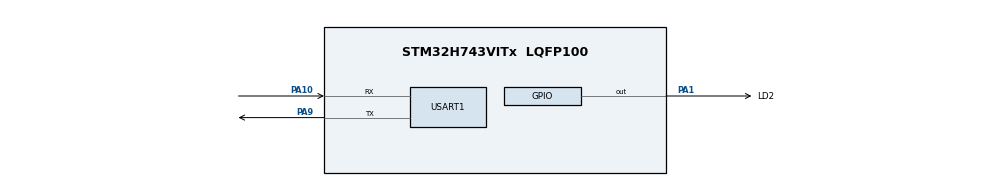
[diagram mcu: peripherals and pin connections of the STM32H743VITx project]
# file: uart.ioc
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Mcu.Family=STM32H7
Mcu.Name=STM32H743VITx
Mcu.Package=LQFP100
NVIC.PriorityGroup=NVIC_PRIORITYGROUP_4
PA1.GPIO_Label=LD2
PA1.Signal=GPIO_Output
PA10.Mode=Asynchronous
PA10.Signal=USART1_RX
PA13\ (JTMS/SWDIO).Mode=Serial_Wire
PA13\ (JTMS/SWDIO).Signal=DEBUG_JTMS-SWDIO
PA14\ (JTCK/SWCLK).Mode=Serial_Wire
PA14\ (JTCK/SWCLK).Signal=DEBUG_JTCK-SWCLK
PA9.Mode=Asynchronous
PA9.Signal=USART1_TX
PC14-OSC32_IN\ (OSC32_IN).Mode=LSE-External-Oscillator
PC14-OSC32_IN\ (OSC32_IN).Signal=RCC_OSC32_IN
PC15-OSC32_OUT\ (OSC32_OUT).Mode=LSE-External-Oscillator
PC15-OSC32_OUT\ (OSC32_OUT).Signal=RCC_OSC32_OUT
PH0-OSC_IN\ (PH0).Mode=HSE-External-Oscillator
PH0-OSC_IN\ (PH0).Signal=RCC_OSC_IN
PH1-OSC_OUT\ (PH1).Mode=HSE-External-Oscillator
PH1-OSC_OUT\ (PH1).Signal=RCC_OSC_OUT
ProjectManager.HeapSize=0x200
ProjectManager.StackSize=0x400
ProjectManager.TargetToolchain=MDK-ARM V5
RCC.ADCFreq_Value=129000000
RCC.APB1Freq_Value=100000000
RCC.APB2Freq_Value=100000000
RCC.APB3Freq_Value=100000000
RCC.APB4Freq_Value=100000000
RCC.CortexFreq_Value=400000000
RCC.D1PPRE=RCC_APB3_DIV2
RCC.D2PPRE1=RCC_APB1_DIV2
RCC.D2PPRE2=RCC_APB2_DIV2
RCC.D3PPRE=RCC_APB4_DIV2
RCC.DIVM1=2
RCC.DIVN1=64
RCC.HCLKFreq_Value=200000000
RCC.HPRE=RCC_HCLK_DIV2
RCC.PLLFRACN=0
RCC.PLLSourceVirtual=RCC_PLLSOURCE_HSE
RCC.SYSCLKFreq_VALUE=400000000
RCC.SYSCLKSource=RCC_SYSCLKSOURCE_PLLCLK
RCC.USBFreq_Value=400000000
USART1.VirtualMode-Asynchronous=VM_ASYNC
board=custom

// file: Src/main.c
/* USER CODE BEGIN Header */
/**
  ******************************************************************************
  * @file           : main.c
  * @brief          : Main program body
  ******************************************************************************
  * @attention
  *
  * <h2><center>&copy; Copyright (c) 2020 STMicroelectronics.
  * All rights reserved.</center></h2>
  *
  * This software component is licensed by ST under BSD 3-Clause license,
  * the "License"; You may not use this file except in compliance with the
  * License. You may obtain a copy of the License at:
  *                        opensource.org/licenses/BSD-3-Clause
  *
  ******************************************************************************
  */
/* USER CODE END Header */

#include "main.h"
#include "usart.h"
#include "gpio.h"

/* USER CODE BEGIN Includes */
#include <stdio.h>
#include "tx_api.h"
/* USER CODE END Includes */

void SystemClock_Config(void);

/* USER CODE BEGIN 0 */
TX_THREAD my_thread1;
TX_THREAD my_thread2;
TX_THREAD my_thread3;

void my_thread1_entry(ULONG thread_input)
{
    /* Enter into a forever loop. */
    while(1)
    {
        printf("threadx 1 application running...\r\n");
        /* Sleep for 1 tick. */
        tx_thread_sleep(1000);
    }
}
void my_thread2_entry(ULONG thread_input)
{
    /* Enter into a forever loop. */
    while(1)
    {
        printf("threadx 2 application running...\r\n");
        /* Sleep for 1 tick. */
        tx_thread_sleep(1000);
    }
}
void my_thread3_entry(ULONG thread_input)
{
    /* Enter into a forever loop. */
    while(1)
    {
        HAL_GPIO_TogglePin(LD2_GPIO_Port, LD2_Pin);
        /* Sleep for 1 tick. */
        tx_thread_sleep(1000);
    }
}

void tx_application_define(void *first_unused_memory)
{
    /* Create my_thread! */
    tx_thread_create(&my_thread1, "My Thread 1",
    my_thread1_entry, 0x1234, first_unused_memory, 1024, 3, 3, TX_NO_TIME_SLICE, TX_AUTO_START);

    tx_thread_create(&my_thread2, "My Thread 2",
    my_thread2_entry, 0x1234, first_unused_memory+1024, 1024, 1, 1, TX_NO_TIME_SLICE, TX_AUTO_START);

    tx_thread_create(&my_thread3, "My Thread 3",
    my_thread3_entry, 0x1234, first_unused_memory+2048, 1024, 4, 4, TX_NO_TIME_SLICE, TX_AUTO_START);
}
/* USER CODE END 0 */

int main(void)
{

  /* MCU Configuration--------------------------------------------------------*/

  /* Reset of all peripherals, Initializes the Flash interface and the Systick. */
  HAL_Init();

  /* Configure the system clock */
  SystemClock_Config();

  /* Initialize all configured peripherals */
  MX_GPIO_Init();
  MX_USART1_UART_Init();
  /* USER CODE BEGIN 2 */
    printf("threadx RTOS on STM32H743VIT6 DevEBox Board\r\n");
    printf("CPUID:%08x %08x %08x\r\n", HAL_GetUIDw0(), HAL_GetUIDw1(), HAL_GetUIDw2());
    printf("HAL Version:%08x\r\n", HAL_GetHalVersion());

    /* Enter the ThreadX kernel. */
    tx_kernel_enter();
  /* USER CODE END 2 */

  /* Infinite loop */
  while (1)
  {

  }
}

void SystemClock_Config(void)
{
  RCC_OscInitTypeDef RCC_OscInitStruct = {0};
  RCC_ClkInitTypeDef RCC_ClkInitStruct = {0};
  RCC_PeriphCLKInitTypeDef PeriphClkInitStruct = {0};

  /** Supply configuration update enable
  */
  HAL_PWREx_ConfigSupply(PWR_LDO_SUPPLY);
  /** Configure the main internal regulator output voltage
  */
  __HAL_PWR_VOLTAGESCALING_CONFIG(PWR_REGULATOR_VOLTAGE_SCALE1);

  while(!__HAL_PWR_GET_FLAG(PWR_FLAG_VOSRDY)) {}
  /** Initializes the CPU, AHB and APB busses clocks
  */
  RCC_OscInitStruct.OscillatorType = RCC_OSCILLATORTYPE_HSE;
  RCC_OscInitStruct.HSEState = RCC_HSE_ON;
  RCC_OscInitStruct.PLL.PLLState = RCC_PLL_ON;
  RCC_OscInitStruct.PLL.PLLSource = RCC_PLLSOURCE_HSE;
  RCC_OscInitStruct.PLL.PLLM = 2;
  RCC_OscInitStruct.PLL.PLLN = 64;
  RCC_OscInitStruct.PLL.PLLP = 2;
  RCC_OscInitStruct.PLL.PLLQ = 2;
  RCC_OscInitStruct.PLL.PLLR = 2;
  RCC_OscInitStruct.PLL.PLLRGE = RCC_PLL1VCIRANGE_3;
  RCC_OscInitStruct.PLL.PLLVCOSEL = RCC_PLL1VCOWIDE;
  RCC_OscInitStruct.PLL.PLLFRACN = 0;
  if (HAL_RCC_OscConfig(&RCC_OscInitStruct) != HAL_OK)
  {
    Error_Handler();
  }
  /** Initializes the CPU, AHB and APB busses clocks
  */
  RCC_ClkInitStruct.ClockType = RCC_CLOCKTYPE_HCLK|RCC_CLOCKTYPE_SYSCLK
                              |RCC_CLOCKTYPE_PCLK1|RCC_CLOCKTYPE_PCLK2
                              |RCC_CLOCKTYPE_D3PCLK1|RCC_CLOCKTYPE_D1PCLK1;
  RCC_ClkInitStruct.SYSCLKSource = RCC_SYSCLKSOURCE_PLLCLK;
  RCC_ClkInitStruct.SYSCLKDivider = RCC_SYSCLK_DIV1;
  RCC_ClkInitStruct.AHBCLKDivider = RCC_HCLK_DIV2;
  RCC_ClkInitStruct.APB3CLKDivider = RCC_APB3_DIV2;
  RCC_ClkInitStruct.APB1CLKDivider = RCC_APB1_DIV2;
  RCC_ClkInitStruct.APB2CLKDivider = RCC_APB2_DIV2;
  RCC_ClkInitStruct.APB4CLKDivider = RCC_APB4_DIV2;

  if (HAL_RCC_ClockConfig(&RCC_ClkInitStruct, FLASH_LATENCY_2) != HAL_OK)
  {
    Error_Handler();
  }
  PeriphClkInitStruct.PeriphClockSelection = RCC_PERIPHCLK_USART1;
  PeriphClkInitStruct.Usart16ClockSelection = RCC_USART16CLKSOURCE_D2PCLK2;
  if (HAL_RCCEx_PeriphCLKConfig(&PeriphClkInitStruct) != HAL_OK)
  {
    Error_Handler();
  }
}

void Error_Handler(void)
{
}

/************************ (C) COPYRIGHT STMicroelectronics *****END OF FILE****/
